# NUC200AE_v1 register map
File version: 1.0
Registers are 32-bit, read-write, reset 0x0 unless marked. A register's access mark holds for its fields unless they carry their own. Offsets are from the block's base; [hi:lo] are bit positions; 'fields as' and 'values as' point back to an identical list.

## SPI0 — SPI Register Map
Base 0x40030000
Same registers: SPI1 0x40034000, SPI2 0x40130000, SPI3 0x40134000
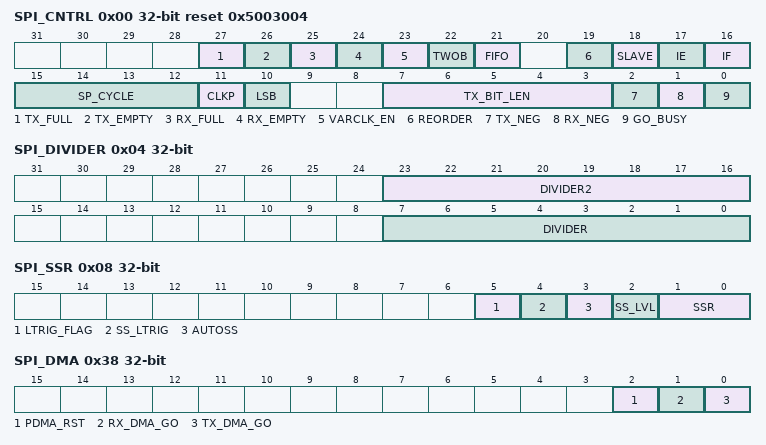
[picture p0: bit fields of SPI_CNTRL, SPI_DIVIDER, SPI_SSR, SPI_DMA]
0x00 SPI_CNTRL reset 0x5003004 — Control and Status Register
  [27] TX_FULL ro — Transmit FIFO Buffer Full Indicator (Read Only). It is a mutual mirror bit of SPI_STATUS[27].
    0=Transmit FIFO buffer is not full; 1=Transmit FIFO buffer is full
  [26] TX_EMPTY ro — Transmit FIFO Buffer Empty Indicator (Read Only). It is a mutual mirror bit of SPI_STATUS[26].
    0=Transmit FIFO buffer is not empty; 1=Transmit FIFO buffer is empty
  [25] RX_FULL ro — Receive FIFO Buffer Full Indicator (Read Only). It is a mutual mirror bit of SPI_STATUS[25].
    0=Receive FIFO buffer is not full; 1=Receive FIFO buffer is full
  [24] RX_EMPTY ro — Receive FIFO Buffer Empty Indicator (Read Only). It is a mutual mirror bit of SPI_CNTRL[24].
    0=Receive FIFO buffer is not empty; 1=Receive FIFO buffer is empty
  [23] VARCLK_EN — Variable Clock Enable Bit (Master Only). Note: When this VARCLK_EN bit is set to 1, the setting of TX_BIT_LEN must be programmed as 0x10 (16-bit mode).
    0=SPI clock output frequency is fixed and decided only by the value of DIVIDER; 1=SPI clock output frequency is variable. The output frequency is decided by the value of VARCLK, DIVIDER, and DIVIDER2
  [22] TWOB — 2-Bit Transfer Mode EnableBit. Note: When 2-bit Transfer mode is enabled, the serial transmitted 2-bit data are from SPI_TX1/0, and the received 2-bit data input are put in SPI_RX1/0.
    0=2-bit Transfer mode Disabled; 1=2-bit Transfer mode Enabled
  [21] FIFO — FIFO Mode EnableBit. Note: Before enabling FIFO mode, the other related settings should be set in advance. In Master mode, if the FIFO mode is enabled, the GO_BUSY bit will be set to 1 automatically after writing data to the transmit FIFO buffer; the GO_BUSY bit will be cleared to 0 automatically when the SPI controller is in idle. If all data stored at transmit FIFO buffer are sent out, the TX_EMPTY bit will be set to 1 and the GO_BUSY bit will be cleared to 0. After clearing this bit to 0, user must wait for at least 2 peripheral clock periods before setting this bit to 1 again.
    0=FIFO mode Disabled; 1=FIFO mode Enabled
  [19] REORDER — Byte Reorder Function EnableBit. Note: Byte Reorder function is only available if TX_BIT_LEN is defined as 16, 24, and 32 bits. In Slave mode with level-trigger configuration, the slave select pin must be kept at active state during the byte suspend interval. The Byte Reorder function is not supported when the variable bus clock function or Dual I/O mode is enabled.
    0=Byte Reorder function Disabled; 1=Byte Reorder function Enabled. A byte suspend interval will be inserted among each byte. The period of the byte suspend interval depends on the setting of SP_CYCLE
  [18] SLAVE — Slave Mode EnableBit
    0=Master mode; 1=Slave mode
  [17] IE — Unit Transfer Interrupt EnableBit
    0=SPI unit transfer interrupt Disabled; 1=SPI unit transfer interrupt Enabled
  [16] IF — Unit Transfer Interrupt Flag. Note: This bit will be cleared by writing 1 to itself.
    0=No transaction has been finished since this bit was cleared to 0; 1=SPI controller has finished one unit transfer
  [15:12] SP_CYCLE — Suspend Interval (Master Only). The four bits provide configurable suspend interval between two successive transmit/receive transaction in a transfer. The definition of the suspend interval is the interval between the last clock edge of the preceding transaction word and the first clock edge of the following transaction word. The default value is 0x3. The period of the suspend interval is obtained according to the following equation. (SP_CYCLE[3:0] + 0.5) * period of SPI bus clock cycle. Example: If the variable clock function is enabled and the transmit FIFO buffer is not empty, the minimum period of suspend interval between the successive transactions is (6.5 + SP_CYCLE) * SPI bus clock cycle.
  [11] CLKP — Clock Polarity
    0=SPI bus clock is idle low; 1=SPI bus clock is idle high
  [10] LSB — Send LSB First
    0=The MSB, which bit of transmit/receive register depends on the setting of TX_BIT_LEN, is transmitted/received first; 1=The LSB, bit 0 of the SPI TX0/1 register, is sent first to the SPI data output pin, and the first bit received from the SPI data input pin will be put in the LSB position of the RX register (bit 0 of SPI_RX0/1)
  [7:3] TX_BIT_LEN — Transmit Bit Length. This field specifies how many bits can be transmitted / received in one transaction. The minimum bit length is 8 bits and can up to 32 bits.
  [2] TX_NEG — Transmit On Negative Edge
    0=Transmitted data output signal is changed on the rising edge of SPI bus clock; 1=Transmitted data output signal is changed on the falling edge of SPI bus clock
  [1] RX_NEG — Receive On Negative Edge
    0=Received data input signal is latched on the rising edge of SPI bus clock; 1=Received data input signal is latched on the falling edge of SPI bus clock
  [0] GO_BUSY — SPI Transfer Control Bit And Busy Status. If FIFO mode is disabled, during the data transfer, this bit keeps the value of 1. As the transfer is finished, this bit will be cleared automatically. Software can read this bit to check if the SPI is in busy status. In FIFO mode, this bit will be controlled by hardware. Software should not modify this bit. In Slave mode, this bit always returns 1 when this register is read by software. In Master mode, this bit reflects the busy or idle status of SPI. Note: When FIFO mode is disabled, all configurations should be set before writing 1 to this GO_BUSY bit. When FIFO mode is disabled and the software uses TX or RX PDMA function to transfer data, this bit will be cleared after the PDMA finishes the data transfer.
    0=Data transfer stopped; 1=In Master mode, writing 1 to this bit to start the SPI data transfer; in Slave mode, writing 1 to this bit indicates that the slave is ready to communicate with a master
0x04 SPI_DIVIDER — Clock Divider Register
  [23:16] DIVIDER2 — Clock Divider 2 Register (Master Only). The value in this field is the 2nd frequency divider for generating the second clock of the variable clock function. The frequency is obtained according to the following equation: . If the VARCLK_EN bit is cleared to 0, this setting is unmeaning.
  [7:0] DIVIDER — Clock Divider 1 Register. The value in this field is the frequency divider for generating the SPI peripheral clock, fspi_eclk, and the SPI bus clock of SPI master. The frequency is obtained according to the following equation. If the bit of BCn, SPI_CNTRL2[31], is set to 0, else if BCn is set to 1, where is the SPI peripheral clock source, which is defined in the CLKSEL1 register.
0x08 SPI_SSR — Slave Select Register
  [5] LTRIG_FLAG — Level Trigger Accomplish Flag. In Slave mode, this bit indicates whether the received bit number meets the requirement or not after the current transaction done. Note: This bit is READ only. As the GO_BUSY bit is set to 1 by software, the LTRIG_FLAG will be cleared to 0 after 4 SPI peripheral clock periods plus 1 system clock period. In FIFO mode, this bit has no meaning.
    0=Transferred bit length of one transaction does not meet the specified requirement; 1=Transferred bit length meets the specified requirement which defined in TX_BIT_LEN
  [4] SS_LTRIG — Slave Select Level Trigger Enable Bit (Slave Only)
    0=Slave select signal is edge-trigger. This is the default value. The SS_LVL bit decides the signal is active after a falling-edge or rising-edge; 1=Slave select signal is level-trigger. The SS_LVL bit decides the signal is active low or active high
  [3] AUTOSS — Automatic Slave Select Function Enable Bit (Master Only)
    0=If this bit is cleared, slave select signals will be asserted/de-asserted by setting /clearing the corresponding bits of SPI_SSR[1:0]; 1=If this bit is set, SPIn_SPISS0/1 signals will be generated automatically. It means that device/slave select signal, which is set in SPI_SSR[1:0], will be asserted by the SPI controller when transmit/receive is started, and will be de-asserted after each transmit/receive is finished
  [2] SS_LVL — Slave Select Active Level. This bit defines the active status of slave select signal (SPIn_SPISS0/1).
    0=The slave select signal SPIn_SPISS0/1 is active on low-level/falling-edge; 1=The slave select signal SPIn_SPISS0/1 is active on high-level/rising-edge
  [1:0] SSR — Slave Select Control Bits (Master Only). If AUTOSS bit is cleared, writing 1 to any bit of this field sets the proper SPIn_SPISS0/1 line to an active state and writing 0 sets the line back to inactive state. If the AUTOSS bit is set, writing 0 to any bit location of this field will keep the corresponding SPIn_SPISS0/1 line at inactive state; writing 1 to any bit location of this field will select appropriate SPIn_SPISS0/1 line to be automatically driven to active state for the duration of the transmit/receive, and will be driven to inactive state for the rest of the time. The active state of SPIn_SPISS0/1 is specified in SS_LVL. Note: SPIn_SPISS0 is defined as the slave select input in Slave mode.
0x10 SPI_RX0 ro — Data Receive Register 0
  [31:0] RX — Data Receive Register. The data receive register holds the datum received from SPI data input pin. If FIFO mode is disabled, the last received data can be accessed through software by reading this register. If the FIFO bit is set as 1 and the RX_EMPTY bit, SPI_CNTRL[24] or SPI_STATUS[24], is not set to 1, the receive FIFO buffer can be accessed through software by reading this register. This is a read-only register.
0x14 SPI_RX1 ro — Data Receive Register 1
  fields as SPI_RX0
0x20 SPI_TX0 wo — Data Transmit Register 0
  [31:0] TX — Data Transmit Register. The data transmit registers hold the data to be transmitted in the next transfer. The number of valid bits depends on the setting of transmit bit length field of the SPI_CNTRL register. For example, if TX_BIT_LEN is set to 0x08, the bits TX[7:0] will be transmitted in next transfer. If TX_BIT_LEN is set to 0x00, the SPI controller will perform a 32-bit transfer. Note 1: When the SPI controller is configured as a slave device and FIFO mode is disabled, if the SPI controller attempts to transmit data to a master, the transmit data register should be updated by software before setting the GO_BUSY bit to 1. Note 2: In Master mode, SPI controller will start to transfer after 5 peripheral clock cycles since user wrote to this register.
0x24 SPI_TX1 wo — Data Transmit Register 1
  fields as SPI_TX0
0x34 SPI_VARCLK reset 0x7FFF87 — Variable Clock Pattern Register
  [31:0] VARCLK — Variable Clock Pattern. This register defines the clock pattern of the SPI transfer. If the variable clock function is disabled, this setting is unmeaning. Refer to the "Variable Clock Function" paragraph for more detail description.
0x38 SPI_DMA — SPI DMA Control Register
  [2] PDMA_RST — PDMA Reset
    0=No effect; 1=Reset the PDMA control logic of the SPI controller. This bit will be cleared to 0 automatically
  [1] RX_DMA_GO — Receive DMA Start. Setting this bit to 1 will start the receive PDMA process. The SPI controller will issue request to PDMA controller automatically when the SPI receive buffer is not empty. This bit will be cleared to 0 by hardware automatically after PDMA transfer is done. If the software uses the receive PDMA function to access the received data of SPI and does not use the transmit PDMA function, the GO_BUSY bit should be set by software. Enabling FIFO mode is recommended if the software uses more than one PDMA channel to transfer data. In Slave mode and when FIFO mode is disabled, if the software only uses one PDMA channel for SPI receive PDMA function and the other PDMA channels are not in use, the minimal suspend interval between two successive transactions must be larger than (9 SPI slave peripheral clock periods + 4 APB clock periods) for Edge-trigger mode or (9.5 SPI slave peripheral clock periods + 4 APB clock periods) for Level-trigger mode.
  [0] TX_DMA_GO — Transmit DMA Start. Setting this bit to 1 will start the transmit PDMA process. SPI controller will issue request to PDMA controller automatically. Hardware will clear this bit to 0 automatically after PDMA transfer done. If the SPI transmit PDMA function is used to transfer data, the GO_BUSY bit should not be set to 1 by software. The PDMA control logic of SPI controller will set it automatically whenever necessary. In Slave mode and when FIFO mode is disabled, the minimal suspend interval between two successive transactions must be larger than (8 SPI clock periods + 14 APB clock periods) for edge-trigger mode or (9.5 SPI clock periods + 14 APB clock periods) for level-trigger mode. If the 2-bit Transfer mode is enabled, additional 18 APB clock periods for the above conditions is required.
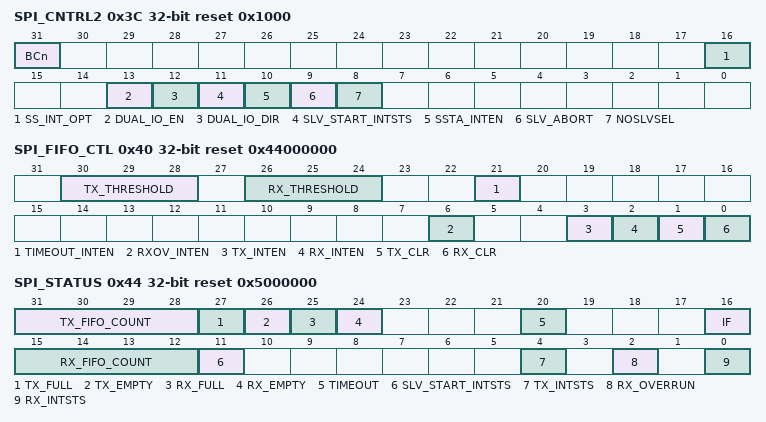
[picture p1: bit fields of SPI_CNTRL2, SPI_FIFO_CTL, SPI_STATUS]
0x3C SPI_CNTRL2 reset 0x1000 — Control and Status Register 2
  [31] BCn — SPI Peripheral Clock Backward Compatible Option. Refer to the description of SPI_DIVIDER register for details.
    0=Backward compatible clock configuration; 1=Clock configuration is not backward compatible
  [16] SS_INT_OPT — Slave Select Inactive Interrupt Option. This setting is only available if the SPI controller is configured as level trigger slave device.
    0=As the slave select signal goes to inactive level, the IF bit will NOT be set to 1; 1=As the slave select signal goes to inactive level, the IF bit will be set to 1
  [13] DUAL_IO_EN — Dual I/O Mode EnableBit
    0=Dual I/O mode Disabled; 1=Dual I/O mode Enabled
  [12] DUAL_IO_DIR — Dual I/O Mode Direction Control
    0=Dual Input mode; 1=Dual Output mode
  [11] SLV_START_INTSTS — Slave 3-Wire Mode Start Interrupt Status. This bit indicates if a transaction has started in Slave 3-wire mode. It is a mutual mirror bit of SPI_STATUS[11].
    0=Slave has not detected any SPI clock transition since the SSTA_INTEN bit was set to 1; 1=A transaction has started in Slave 3-wire mode. It will be cleared automatically when a transaction is done or by writing 1 to this bit
  [10] SSTA_INTEN — Slave 3-Wire Mode Start Interrupt EnableBit. Used to enable interrupt when the transfer has started in Slave 3-wire mode. If there is no transfer done interrupt over the time period which is defined by user after the transfer start, the user can set the SLV_ABORT bit to force the transfer done.
    0=Transaction start interrupt Disabled; 1=Transaction start interrupt Enabled. It will be cleared to 0 as the current transfer is done or the SLV_START_INTSTS bit is cleared
  [9] SLV_ABORT — Slave 3-Wire Mode Abort Control. In normal operation, there is an interrupt event when the received data meet the required bits which defined in TX_BIT_LEN. If the received bits are less than the requirement and there is no more SPI clock input over the one transfer time in Slave 3-wire mode, the user can set this bit to force the current transfer done and then the user can get a transfer done interrupt event. Note: This bit will be cleared to 0 automatically by hardware after it is set to 1 by software.
  [8] NOSLVSEL — Slave 3-Wire Mode Enable Bit. This is used to ignore the slave select signal in Slave mode. The SPI controller can work with 3-wire interface including SPIn_CLK, SPIn_MISO, and SPIn_MOSI. Note: In Slave 3-wire mode, the SS_LTRIG, SPI_SSR[4] will be set as 1 automatically.
    0=4-wire bi-direction interface; 1=3-wire bi-direction interface
0x40 SPI_FIFO_CTL reset 0x44000000 — SPI FIFO Control Register
  [30:28] TX_THRESHOLD — Transmit FIFO Threshold. If the valid data count of the transmit FIFO buffer is less than or equal to the TX_THRESHOLD setting, the TX_INTSTS bit will be set to 1, else the TX_INTSTS bit will be cleared to 0.
  [26:24] RX_THRESHOLD — Receive FIFO Threshold. If the valid data count of the receive FIFO buffer is larger than the RX_THRESHOLD setting, the RX_INTSTS bit will be set to 1, else the RX_INTSTS bit will be cleared to 0.
  [21] TIMEOUT_INTEN — Receive FIFO Time-Out Interrupt Enable Bit
    0=Time-out interrupt Disabled; 1=Time-out interrupt Enabled
  [6] RXOV_INTEN — Receive FIFO Overrun Interrupt Enable Bit
    0=Receive FIFO overrun interrupt Disabled; 1=Receive FIFO overrun interrupt Enabled
  [3] TX_INTEN — Transmit Threshold Interrupt Enable Bit
    0=TX threshold interrupt Disabled; 1=TX threshold interrupt Enabled
  [2] RX_INTEN — Receive Threshold Interrupt Enable Bit
    0=RX threshold interrupt Disabled; 1=RX threshold interrupt Enabled
  [1] TX_CLR — Clear Transmit FIFO Buffer
    0=No effect; 1=Clear transmit FIFO buffer. The TX_FULL flag will be cleared to 0 and the TX_EMPTY flag will be set to 1. This bit will be cleared to 0 by hardware after it is set to 1 by software
  [0] RX_CLR — Clear Receive FIFO Buffer
    0=No effect; 1=Clear receive FIFO buffer. The RX_FULL flag will be cleared to 0 and the RX_EMPTY flag will be set to 1. This bit will be cleared to 0 by hardware after it is set to 1 by software
0x44 SPI_STATUS reset 0x5000000
  [31:28] TX_FIFO_COUNT ro — Transmit FIFO Data Count (Read Only). This bit field indicates the valid data count of transmit FIFO buffer.
  [27] TX_FULL ro — Transmit FIFO Buffer Full Indicator (Read Only). It is a mutual mirror bit of SPI_CNTRL[27].
    values as SPI_CNTRL.TX_FULL
  [26] TX_EMPTY ro — Transmit FIFO Buffer Empty Indicator (Read Only). It is a mutual mirror bit of SPI_CNTRL[26].
    values as SPI_CNTRL.TX_EMPTY
  [25] RX_FULL ro — Receive FIFO Buffer Empty Indicator (Read Only). It is a mutual mirror bit of SPI_CNTRL[24].
    values as SPI_CNTRL.RX_EMPTY
  [24] RX_EMPTY ro — Receive FIFO Buffer Empty Indicator (Read Only). It is a mutual mirror bit of SPI_CNTRL[24].
    values as SPI_CNTRL.RX_EMPTY
  [20] TIMEOUT — Time-Out Interrupt Flag. Note: This bit will be cleared by writing 1 to itself.
    0=No receive FIFO time-out event; 1=Receive FIFO buffer is not empty and no read operation on receive FIFO buffer over 64 SPI clock period in Master mode or over 576 SPI peripheral clock period in Slave mode. When the received FIFO buffer is read by software, the time-out status will be cleared automatically
  [16] IF — SPI Unit Transfer Interrupt Flag. It is a mutual mirror bit of SPI_CNTRL[16]. Note: This bit will be cleared by writing 1 to itself.
    values as SPI_CNTRL.IF
  [15:12] RX_FIFO_COUNT ro — Receive FIFO Data Count (Read Only). This bit field indicates the valid data count of receive FIFO buffer.
  [11] SLV_START_INTSTS — Slave Start Interrupt Status. It is used to dedicate if a transaction has started in Slave 3-wire mode. It is a mutual mirror bit of SPI_CNTRL2[11].
    0=Slave has not detected any SPI clock transition since the SSTA_INTEN bit was set to 1; 1=A transaction has started in Slave 3-wire mode. It will be cleared as a transaction is done or by writing 1 to this bit
  [4] TX_INTSTS ro — Transmit FIFO Threshold Interrupt Status (Read Only)
    0=The valid data count within the transmit FIFO buffer is larger than the setting value of TX_THRESHOLD; 1=The valid data count within the transmit FIFO buffer is less than or equal to the setting value of TX_THRESHOLD
  [2] RX_OVERRUN — Receive FIFO Overrun Status. When the receive FIFO buffer is full, the follow-up data will be dropped and this bit will be set to 1. Note: This bit will be cleared by writing 1 to itself.
  [0] RX_INTSTS ro — Receive FIFO Threshold Interrupt Status (Read Only)
    0=The valid data count within the Rx FIFO buffer is smaller than or equal to the setting value of RX_THRESHOLD; 1=The valid data count within the receive FIFO buffer is larger than the setting value of RX_THRESHOLD
